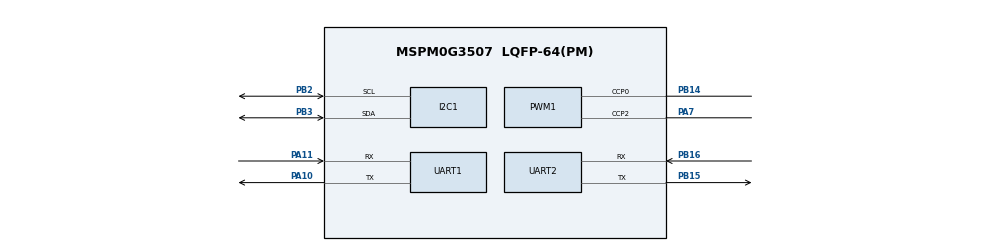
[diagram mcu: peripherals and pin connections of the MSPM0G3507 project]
//@cliArgs --device "MSPM0G350X" --package "LQFP-64(PM)" --part "Default"
//@v2CliArgs --device "MSPM0G3507" --package "LQFP-64(PM)"
// @cliArgs --board /ti/boards/LP_MSPM0G3507 --rtos nortos

/**
 * Import the modules used in this configuration.
 */
const GPIO   = scripting.addModule("/ti/driverlib/GPIO", {}, false);
const GPIO1  = GPIO.addInstance();
const GPIO2  = GPIO.addInstance();
const GPIO3  = GPIO.addInstance();
const I2C    = scripting.addModule("/ti/driverlib/I2C", {}, false);
const I2C1   = I2C.addInstance();
const PWM    = scripting.addModule("/ti/driverlib/PWM", {}, false);
const PWM1   = PWM.addInstance();
const SYSCTL = scripting.addModule("/ti/driverlib/SYSCTL");
const TIMER  = scripting.addModule("/ti/driverlib/TIMER", {}, false);
const TIMER1 = TIMER.addInstance();
const UART   = scripting.addModule("/ti/driverlib/UART", {}, false);
const UART1  = UART.addInstance();
const UART2  = UART.addInstance();

/**
 * Write custom configuration values to the imported modules.
 */
GPIO1.$name = "GPIO_TB6612_CTRL";
GPIO1.associatedPins.create(4);
GPIO1.associatedPins[0].$name        = "M1_AIN1";
GPIO1.associatedPins[0].assignedPort = "PORTB";
GPIO1.associatedPins[0].assignedPin  = "9";
GPIO1.associatedPins[1].$name        = "M1_AIN2";
GPIO1.associatedPins[1].assignedPort = "PORTB";
GPIO1.associatedPins[1].assignedPin  = "10";
GPIO1.associatedPins[2].$name        = "M2_BIN1";
GPIO1.associatedPins[2].assignedPort = "PORTB";
GPIO1.associatedPins[2].assignedPin  = "7";
GPIO1.associatedPins[3].$name        = "M2_BIN2";
GPIO1.associatedPins[3].assignedPort = "PORTB";
GPIO1.associatedPins[3].assignedPin  = "6";

GPIO2.$name = "GPIO_ENCODER";
GPIO2.associatedPins.create(4);
GPIO2.associatedPins[0].$name            = "ENCODER_LEFT_A";
GPIO2.associatedPins[0].direction        = "INPUT";
GPIO2.associatedPins[0].assignedPort     = "PORTB";
GPIO2.associatedPins[0].assignedPin      = "11";
GPIO2.associatedPins[0].internalResistor = "PULL_UP";
GPIO2.associatedPins[0].interruptEn      = true;
GPIO2.associatedPins[0].polarity         = "RISE_FALL";
GPIO2.associatedPins[1].$name            = "ENCODER_LEFT_B";
GPIO2.associatedPins[1].direction        = "INPUT";
GPIO2.associatedPins[1].assignedPort     = "PORTB";
GPIO2.associatedPins[1].assignedPin      = "12";
GPIO2.associatedPins[1].internalResistor = "PULL_UP";
GPIO2.associatedPins[2].$name            = "ENCODER_RIGHT_A";
GPIO2.associatedPins[2].direction        = "INPUT";
GPIO2.associatedPins[2].assignedPort     = "PORTB";
GPIO2.associatedPins[2].assignedPin      = "4";
GPIO2.associatedPins[2].internalResistor = "PULL_UP";
GPIO2.associatedPins[2].interruptEn      = true;
GPIO2.associatedPins[2].polarity         = "RISE_FALL";
GPIO2.associatedPins[3].$name            = "ENCODER_RIGHT_B";
GPIO2.associatedPins[3].direction        = "INPUT";
GPIO2.associatedPins[3].assignedPort     = "PORTB";
GPIO2.associatedPins[3].assignedPin      = "5";
GPIO2.associatedPins[3].internalResistor = "PULL_UP";

GPIO3.$name = "GPIO_KEYS";
GPIO3.associatedPins.create(4);
GPIO3.associatedPins[0].$name            = "KEY1";
GPIO3.associatedPins[0].direction        = "INPUT";
GPIO3.associatedPins[0].assignedPort     = "PORTA";
GPIO3.associatedPins[0].assignedPin      = "23";
GPIO3.associatedPins[0].internalResistor = "PULL_UP";
GPIO3.associatedPins[1].$name            = "KEY2";
GPIO3.associatedPins[1].direction        = "INPUT";
GPIO3.associatedPins[1].assignedPort     = "PORTA";
GPIO3.associatedPins[1].assignedPin      = "21";
GPIO3.associatedPins[1].internalResistor = "PULL_UP";
GPIO3.associatedPins[2].$name            = "KEY3";
GPIO3.associatedPins[2].direction        = "INPUT";
GPIO3.associatedPins[2].assignedPort     = "PORTB";
GPIO3.associatedPins[2].assignedPin      = "18";
GPIO3.associatedPins[2].internalResistor = "PULL_UP";
GPIO3.associatedPins[3].$name            = "KEY4";
GPIO3.associatedPins[3].direction        = "INPUT";
GPIO3.associatedPins[3].assignedPort     = "PORTA";
GPIO3.associatedPins[3].assignedPin      = "17";
GPIO3.associatedPins[3].internalResistor = "PULL_UP";

I2C1.$name                     = "I2C_MPU6050";
I2C1.basicEnableController     = true;
I2C1.basicControllerBusSpeed   = 400000;
I2C1.peripheral.sclPin.$assign = "PB2";
I2C1.peripheral.sdaPin.$assign = "PB3";

PWM1.$name                      = "PWM_TB6612";
PWM1.clockPrescale              = 1;
PWM1.timerCount                 = 2000;
PWM1.pwmMode                    = "EDGE_ALIGN_UP";
PWM1.ccIndex                    = [0,2];
PWM1.peripheral.$assign         = "TIMA0";
PWM1.peripheral.ccp0Pin.$assign = "PB14"; /* PWMA */
PWM1.peripheral.ccp2Pin.$assign = "PA7";  /* PWMB */
PWM1.PWM_CHANNEL_0.$name        = "M1_PWM";
PWM1.PWM_CHANNEL_2.$name        = "M2_PWM";

TIMER1.$name              = "TIMER_CTRL_TICK";
TIMER1.profile            = "Basic_Periodic";
TIMER1.peripheral.$assign = "TIMG6";

UART1.$name                    = "UART_OPENMV";
UART1.enableFIFO               = true;
UART1.enableDMARX              = false;
UART1.enableDMATX              = false;
UART1.targetBaudRate           = 115200;
UART1.peripheral.$assign       = "UART0";
UART1.peripheral.txPin.$assign = "PA10";
UART1.peripheral.rxPin.$assign = "PA11";

UART2.$name                    = "UART_HAND_PID";
UART2.enableFIFO               = true;
UART2.enableDMARX              = false;
UART2.enableDMATX              = false;
UART2.targetBaudRate           = 115200;
UART2.peripheral.$assign       = "UART2";
UART2.peripheral.txPin.$assign = "PB15";
UART2.peripheral.rxPin.$assign = "PB16";

const Board = scripting.addModule("/ti/driverlib/Board", {}, false);

SYSCTL.forceDefaultClkConfig = true;
SYSCTL.clockTreeEn           = true;
